# AT32F455xx_v2 register map
Vendor: Keil; Series: AT32F455; File version: 1.0
CPU: CM4 r0p1, little endian, no MPU, FPU, 4 interrupt priority bits
Registers are 32-bit, read-write, reset 0x0 unless marked. A register's access mark holds for its fields unless they carry their own. Offsets are from the block's base; [hi:lo] are bit positions; {n}, {i} and the like mark numbered series.

## USB_OTG1_PWRCLK — USB on the go full speed
Base 0x50000E00
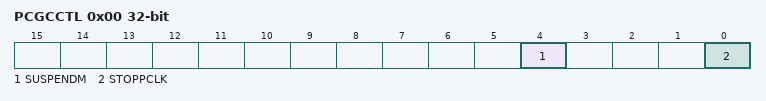
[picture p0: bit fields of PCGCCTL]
0x00 PCGCCTL — OTGFS power and clock gating control register (OTGFS_PCGCCTL)
  [4] SUSPENDM ro — PHY Suspended
  [0] STOPPCLK — Stop PHY clock

## SCFG — System configuration controller
Base 0x40013800
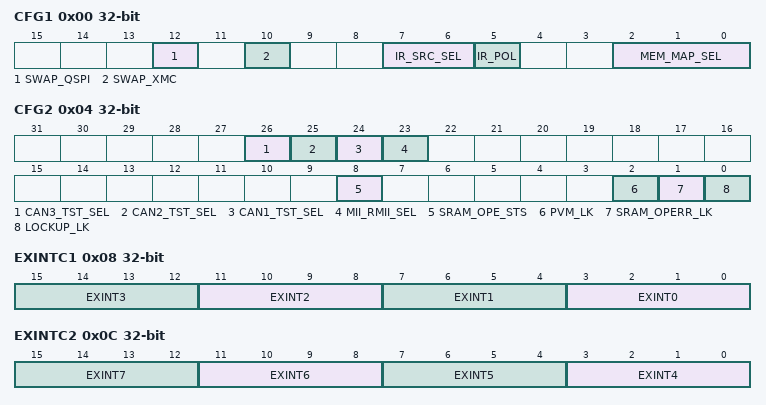
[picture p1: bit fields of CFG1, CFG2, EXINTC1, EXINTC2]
0x00 CFG1 — configuration register 1
  [12] SWAP_QSPI — QSOU address mapping swap
  [10] SWAP_XMC — XMC address mapping swap
  [7:6] IR_SRC_SEL — IR signal source selection
  [5] IR_POL — IR output polarity selection
  [2:0] MEM_MAP_SEL — Memory address mapping selection bits
0x04 CFG2 — configuration register 2
  [26] CAN3_TST_SEL — CAN3 timestamp counting source select
  [25] CAN2_TST_SEL — CAN2 timestamp counting source select
  [24] CAN1_TST_SEL — CAN1 timestamp counting source select
  [23] MII_RMII_SEL — MII or RMII selection bits
  [8] SRAM_OPE_STS — SRAM odd parity error status
  [2] PVM_LK — PVM lock config
  [1] SRAM_OPERR_LK — SRAM odd parity error lock config
  [0] LOCKUP_LK — cm4f lockup config
0x08 EXINTC1 — external interrupt configuration register 1
  [4n+3:4n] EXINT{n} (n=0..3) — EXINT {n} configuration bits
0x0C EXINTC2 — external interrupt configuration register 2
  [4n-13:4n-16] EXINT{n} (n=4..7) — EXINT {n} configuration bits
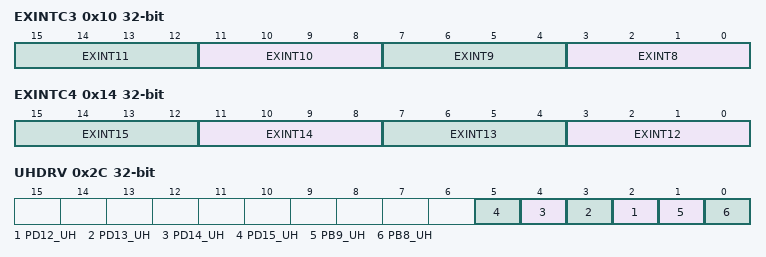
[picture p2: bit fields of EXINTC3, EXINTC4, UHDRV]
0x10 EXINTC3 — external interrupt configuration register 3
  [4n-29:4n-32] EXINT{n} (n=8..11) — EXINT {n} configuration bits
0x14 EXINTC4 — external interrupt configuration register 4
  [4n-45:4n-48] EXINT{n} (n=12..15) — EXINT {n} configuration bits
0x2C UHDRV — Ultra high drive register
  [n-10] PD{n}_UH (n=12..15) — PD{n} ultra high sourcing/sinking strength
  [1] PB9_UH — PB9 ultra high sourcing/sinking strength
  [0] PB8_UH — PB8 ultra high sourcing/sinking strength

## QSPI1 — Quad SPI Controller
Base 0xA0001000
0x00 CMD_W0 — Command word 0
  [31:0] SPIADR — SPI flash address
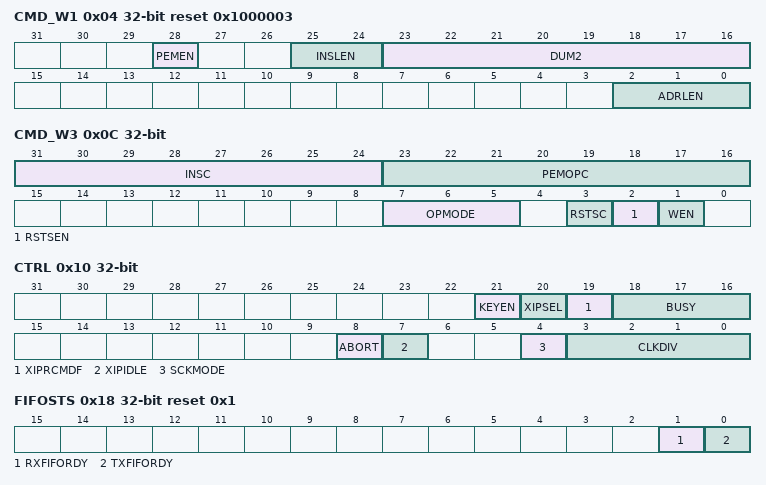
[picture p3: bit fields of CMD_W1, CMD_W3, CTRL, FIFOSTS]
0x04 CMD_W1 reset 0x1000003 — Command word 1
  [28] PEMEN — Perfrmance enhance mode enable
  [25:24] INSLEN — Instruction code length
  [23:16] DUM2 — Second dummy state cycle
  [2:0] ADRLEN — SPI address length
0x08 CMD_W2 reset 0x1000003 — Command word 2
  [31:0] DCNT — Read write data counter
0x0C CMD_W3 — Command word 3
  [31:24] INSC — Instruction code
  [23:16] PEMOPC — Performance enhance mode operate code
  [7:5] OPMODE — SPI operate mode
  [3] RSTSC — Read spi status configure
  [2] RSTSEN — Read spi status enable
  [1] WEN — Write data enable
0x10 CTRL — Control register
  [21] KEYEN — encryption key enable
  [20] XIPSEL — XIP port selection
  [19] XIPRCMDF — XIP read command flush
  [18:16] BUSY — Busy bit of spi status
  [8] ABORT — Abort instruction
  [7] XIPIDLE — XIP port idle status
  [4] SCKMODE — Sckout mode
  [3:0] CLKDIV — SPI clock divider
0x18 FIFOSTS ro reset 0x1 — FIFO Status register
  [1] RXFIFORDY — RxFIFO ready status
  [0] TXFIFORDY — TxFIFO ready status
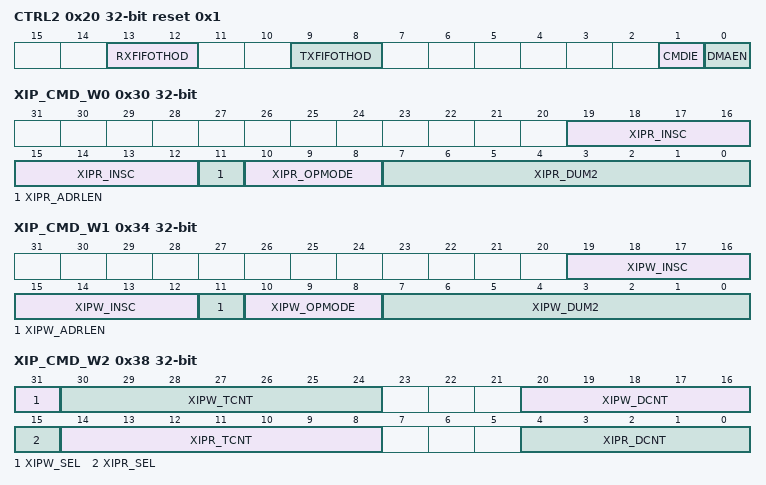
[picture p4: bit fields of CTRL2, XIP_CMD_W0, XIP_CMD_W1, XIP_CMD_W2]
0x20 CTRL2 reset 0x1 — control register 2
  [13:12] RXFIFOTHOD
  [9:8] TXFIFOTHOD
  [1] CMDIE — Command complete interrupt enable
  [0] DMAEN — DMA handshake enable
0x24 CMDSTS ro — CMD status register
  [0] CMDSTS — Command complete status
0x28 RSTS ro — SPI read status register
  [7:0] SPISTS — SPI read status
0x2C FSIZE — SPI flash size
  [31:0] SPIFSIZE
0x30 XIP_CMD_W0 — XIP command word 0
  [19:12] XIPR_INSC — XIP read instruction code
  [11] XIPR_ADRLEN — XIP read address length
  [10:8] XIPR_OPMODE — XIP read operate mode
  [7:0] XIPR_DUM2 — XIP read second dummy cycle
0x34 XIP_CMD_W1 — XIP command word 1
  [19:12] XIPW_INSC — XIP write instruction code
  [11] XIPW_ADRLEN — XIP write address length
  [10:8] XIPW_OPMODE — XIP write operate mode
  [7:0] XIPW_DUM2 — XIP write second dummy cycle
0x38 XIP_CMD_W2 — XIP command word 2
  [31] XIPW_SEL — XIP write continue mode select
  [30:24] XIPW_TCNT — XIP continue write cycle counter
  [20:16] XIPW_DCNT — XIP write data counter
  [15] XIPR_SEL — XIP read continue mode select
  [14:8] XIPR_TCNT — XIP continue read cycle counter
  [4:0] XIPR_DCNT — XIP read data counter
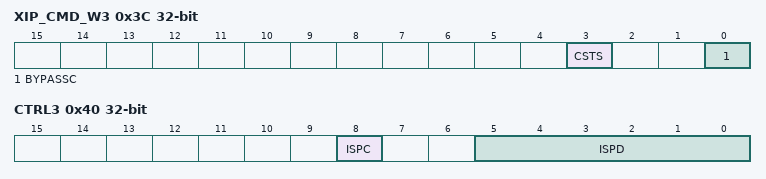
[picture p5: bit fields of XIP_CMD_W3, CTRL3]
0x3C XIP_CMD_W3 — XIP command word 3
  [3] CSTS — Cache status
  [0] BYPASSC — Bypass cache function
0x40 CTRL3 — control register 3
  [8] ISPC — Input sampling phase correction enable
  [5:0] ISPD — Input sampling phase delay
0x50 REV reset 0x10500 — Revision
  [30:0] REVISION — Revision number
0x100 DT — 32/16/8 bit data port register

## AES — AES Controller
Base 0x50060000
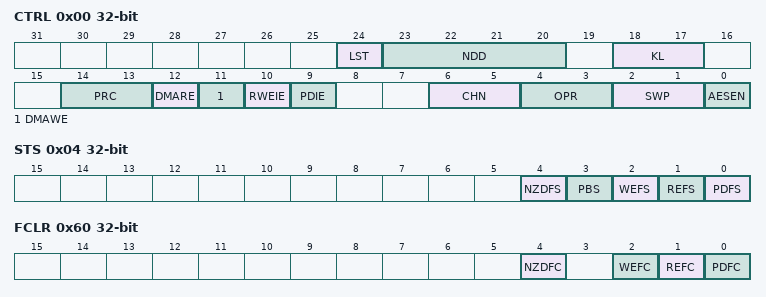
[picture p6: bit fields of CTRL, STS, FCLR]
0x00 CTRL — Control register
  [24] LST — Processing last block
  [23:20] NDD — Number of dummy data
  [18:17] KL — Key length
  [14:13] PRC — Processing stage
  [12] DMARE — DMA read channel enable
  [11] DMAWE — DMA write channel enable
  [10] RWEIE — Read and write error interrupt enable
  [9] PDIE — Processing done interrupt enable
  [6:5] CHN — Chaining mode
  [4:3] OPR — Encrypt/Decrypt mode
  [2:1] SWP — Data swap
  [0] AESEN — AES enable
0x04 STS ro — Status register
  [4] NZDFS — Non-zero dummy data processing flag status
  [3] PBS — Busy status
  [2] WEFS — Write error status
  [1] REFS — Read error status
  [0] PDFS — Processing done status
0x08 IDT wo — Input data port
0x0C ODT ro — Output data port
{0x10+4i} KEY{i} (i=0..3) — Key W{i} register
{0x20+4i} IV{i} (i=0..3) — Initial victor W{i} register
{0x20+4i} KEY{i} (i=4..7) — Key W{i} register
{0x40+4i} SI{i} (i=0..7) — Suspend information W{i} register
0x60 FCLR wo — Flag clear register
  [4] NZDFC — Non-zero dummy data processed flag clear
  [2] WEFC — Write error flag clear
  [1] REFC — Read error flag clear
  [0] PDFC — processing done flag clear

## TRNG — True Random Number Generator
Base 0x50060800
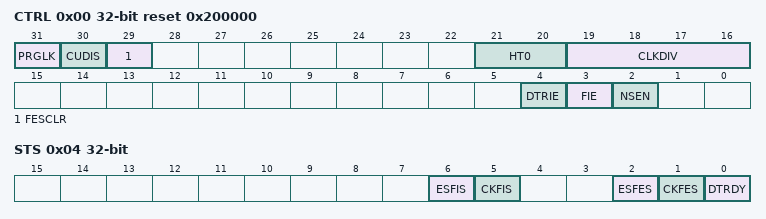
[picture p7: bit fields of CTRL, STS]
0x00 CTRL reset 0x200000 — Control register
  [31] PRGLK — Programing register lock
  [30] CUDIS — Conditioning unit and output buffer disable
  [29] FESCLR — Clock fail event and entropy source fail event status clear
  [21:20] HT0 — Health test parameter 0
  [19:16] CLKDIV — Noise source clock divider factor
  [4] DTRIE — Data port ready interrupt enable
  [3] FIE — Fail interrupt enable
  [2] NSEN — Noise source enable
0x04 STS — Status register
  [6] ESFIS — Entropy source fail interrupt status
  [5] CKFIS — Clock fail interrupt status
  [2] ESFES — Entropy source fail event status
  [1] CKFES — Clock fail event status
  [0] DTRDY — Data port ready
0x08 DT ro — Data port
0x0C HTCTRL reset 0x42CE8 — Health test controller
  [19:0] HT1 — Health test parameter 1
